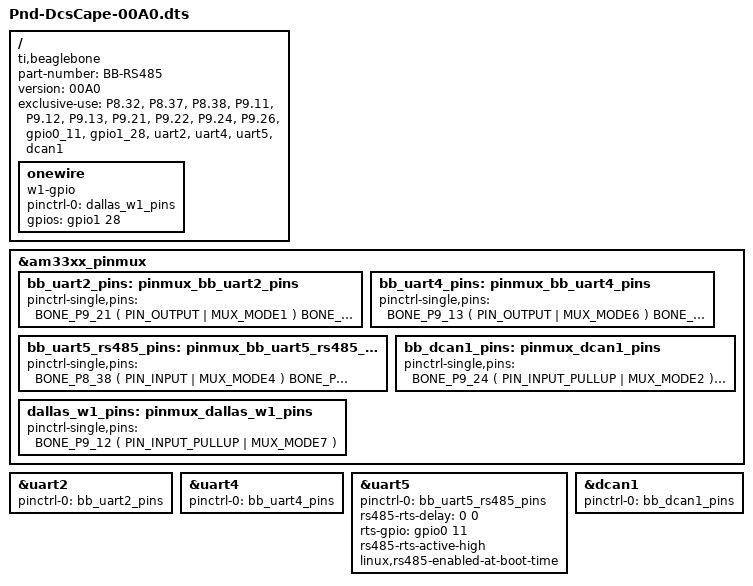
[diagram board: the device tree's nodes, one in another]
/*
 * Copyright (C) 2015 Florian Feldbauer <feldbaue@kph.uni-mainz.de>
 *
 * PANDA DCS Cape Board overlay
 * HDMI cape has to be disapled in order to use UART5!
 *
 * This program is free software; you can redistribute it and/or modify
 * it under the terms of the GNU General Public License as published by
 * the Free Software Foundation; either version 3 of the License, or
 * (at your option) any later version.
 */

/dts-v1/;
/plugin/;

#include <dt-bindings/board/am335x-bbw-bbb-base.h>
#include <dt-bindings/gpio/gpio.h>
#include <dt-bindings/pinctrl/am33xx.h>

/{
  compatible = "ti,beaglebone", "ti,beaglebone-black";

  // identification
  part-number = "BB-RS485";
  version = "00A0";

  // state the resources this cape uses
  exclusive-use =
    // the pin header uses
    "P8.32",  // uart5_rtsn
    "P8.37",	// uart5_txd
    "P8.38",	// uart5_rxd
    "P9.11",  // uart4_rxd
    "P9.12",  // D1W
    "P9.13",  // uart4_txd
    "P9.21",  // uart2_txd
    "P9.22",  // uart2_rxd
    "P9.24",	// can1_rx
    "P9.26",	// can1_tx
		/* the hardware ip uses */
    "gpio0_11",
    "gpio1_28",
    "uart2",
    "uart4",
    "uart5",
    "dcan1";

  fragment@0 {
    target = <&am33xx_pinmux>;
    __overlay__ {
      bb_uart2_pins: pinmux_bb_uart2_pins {
        pinctrl-single,pins = <
          BONE_P9_21 ( PIN_OUTPUT          | MUX_MODE1 )
          BONE_P9_22 ( PIN_INPUT           | MUX_MODE1 )
        >;
      };

      bb_uart4_pins: pinmux_bb_uart4_pins {
        pinctrl-single,pins = <
          BONE_P9_13 ( PIN_OUTPUT          | MUX_MODE6 )
          BONE_P9_11 ( PIN_INPUT           | MUX_MODE6 )
        >;
      };

      bb_uart5_rs485_pins: pinmux_bb_uart5_rs485_pinux {
        pinctrl-single,pins = <
          BONE_P8_38 ( PIN_INPUT           | MUX_MODE4 )
          BONE_P8_37 ( PIN_OUTPUT          | MUX_MODE4 )
          BONE_P8_32 ( PIN_OUTPUT_PULLDOWN | MUX_MODE7 )
        >;
      };

      bb_dcan1_pins: pinmux_dcan1_pins {
        pinctrl-single,pins = <
          BONE_P9_24 ( PIN_INPUT_PULLUP    | MUX_MODE2 )
          BONE_P9_26 ( PIN_OUTPUT_PULLUP   | MUX_MODE2 )
        >;
      };
                      
      dallas_w1_pins: pinmux_dallas_w1_pins {
        pinctrl-single,pins = < 
          BONE_P9_12 ( PIN_INPUT_PULLUP    | MUX_MODE7 )
        >;
      };

    };
  };

  fragment@1 {
    target = <&uart2>;
    __overlay__ {
      status = "okay";
      pinctrl-names = "default";
      pinctrl-0 = <&bb_uart2_pins>;
    };
  };

  fragment@2 {
    target = <&uart4>;
    __overlay__ {
      status = "okay";
      pinctrl-names = "default";
      pinctrl-0 = <&bb_uart4_pins>;
    };
  };

  fragment@3 {
    target = <&uart5>;
    __overlay__ {
      status = "okay";
      pinctrl-names = "default";
      pinctrl-0 = <&bb_uart5_rs485_pins>;

      rs485-rts-delay = <0 0>;
      rts-gpio = <&gpio0 11 GPIO_ACTIVE_HIGH>;
      rs485-rts-active-high;
      linux,rs485-enabled-at-boot-time;
    };
  };

  fragment@4 {
    target = <&dcan1>;
    __overlay__ {
      status = "okay";
      pinctrl-names = "default";
      pinctrl-0 = <&bb_dcan1_pins>;
    };
  };

  fragment@5 {
		target-path = "/";
		__overlay__ {

      onewire {
        status = "okay";
        pinctrl-names = "default";
        pinctrl-0 = <&dallas_w1_pins>;

        compatible = "w1-gpio";
        gpios = <&gpio1 28 GPIO_ACTIVE_HIGH>;
      };
    };  
  };
};

